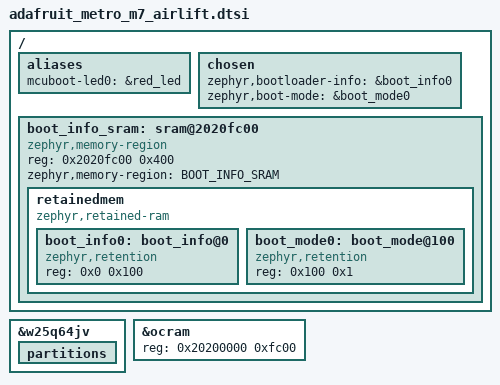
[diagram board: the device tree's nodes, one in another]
/* Board-specific overlay glue for adafruit_metro_m7_airlift.
 *
 * Hand-maintained: device enablement (status = "okay"), delete-nodes
 * for partitions that must be replaced, aliases and chosen nodes. The
 * flash partition layout lives in adafruit_metro_m7_airlift-partitions.dtsi, which is
 * generated by tools/partition_layout.py --fix and included below.
 */

/* Delete the storage partition so we can replace it with nvm + filesystem,
 * and the image-1 partition, which this single-app layout does not use and
 * which would otherwise overlap the filesystem. */
&w25q64jv {
	partitions {
		/delete-node/ partition@320000;
		/delete-node/ partition@620000;
	};
};

/* Bootloader UI: the board has no user button, so the update mode is
 * entered by a double tap of the reset button or by an application
 * request (see conf/adafruit/adafruit_metro_m7_airlift.conf). Point mcuboot-led0 at the red
 * D13 LED so a CONFIG_MCUBOOT_INDICATION_LED build has a status LED. */
/ {
	aliases {
		mcuboot-led0 = &red_led;
	};
};

#include "adafruit_metro_m7_airlift-partitions.dtsi"

/* Bootloader info shared-data area and boot-mode flag: the last KB of
 * OCRAM, as on mimxrt1010_evk (see dts/nxp/mimxrt1010_evk.dtsi for the
 * details). The boot ROM's data and stack occupy only
 * 0x2020_0000-0x2020_57FF (IMXRT1010RM 9.5.1), so this block keeps its
 * contents across a warm reset.
 */
&ocram {
	reg = <0x20200000 0xfc00>;
};

/ {
	chosen {
		zephyr,bootloader-info = &boot_info0;
		zephyr,boot-mode = &boot_mode0;
	};

	boot_info_sram: sram@2020fc00 {
		compatible = "zephyr,memory-region", "mmio-sram";
		reg = <0x2020fc00 0x400>;
		zephyr,memory-region = "BOOT_INFO_SRAM";
		status = "okay";

		retainedmem {
			compatible = "zephyr,retained-ram";
			status = "okay";
			#address-cells = <1>;
			#size-cells = <1>;

			boot_info0: boot_info@0 {
				compatible = "zephyr,retention";
				status = "okay";
				reg = <0x0 0x100>;
			};

			boot_mode0: boot_mode@100 {
				compatible = "zephyr,retention";
				status = "okay";
				reg = <0x100 0x1>;
			};
		};
	};
};
